VERSION "Emergency_System_CAN_Infotainment_v1.3"

NS_ :

BS_:

BU_: SIL_TEST_CTRL INFOTAINMENT_GW IVI_GW CLU_HMI_CTRL NAV_CONTEXT_MGR CLUSTER_BASE_CTRL Vector__XXX

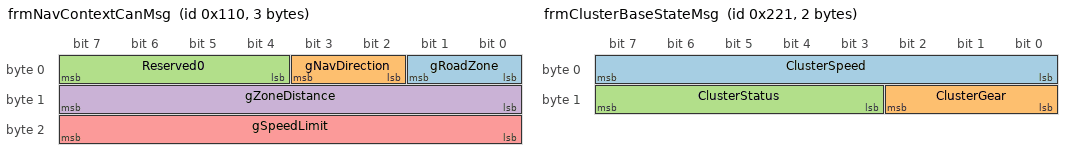
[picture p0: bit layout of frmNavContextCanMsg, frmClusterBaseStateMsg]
BO_ 272 frmNavContextCanMsg: 3 SIL_TEST_CTRL
 SG_ gRoadZone        : 0|2@1+ (1,0) [0|3] "" INFOTAINMENT_GW
 SG_ gNavDirection    : 2|2@1+ (1,0) [0|3] "" INFOTAINMENT_GW
 SG_ Reserved0        : 4|4@1+ (1,0) [0|0] "" Vector__XXX
 SG_ gZoneDistance    : 8|8@1+ (1,0) [0|255] "m" INFOTAINMENT_GW
 SG_ gSpeedLimit      : 16|8@1+ (1,0) [0|255] "km/h" INFOTAINMENT_GW

BO_ 544 frmClusterWarningMsg: 1 IVI_GW
 SG_ WarningTextCode  : 0|8@1+ (1,0) [0|255] "" CLU_HMI_CTRL

BO_ 545 frmClusterBaseStateMsg: 2 IVI_GW
 SG_ ClusterSpeed     : 0|8@1+ (1,0) [0|255] "km/h" CLUSTER_BASE_CTRL
 SG_ ClusterGear      : 8|3@1+ (1,0) [0|7] "" CLUSTER_BASE_CTRL
 SG_ ClusterStatus    : 11|5@1+ (1,0) [0|31] "" CLUSTER_BASE_CTRL

BO_ 546 frmNaviGuideStateMsg: 1 INFOTAINMENT_GW
 SG_ GuideLaneState   : 0|2@1+ (1,0) [0|3] "" NAV_CONTEXT_MGR
 SG_ GuideConfidence  : 2|6@1+ (1,0) [0|63] "" NAV_CONTEXT_MGR

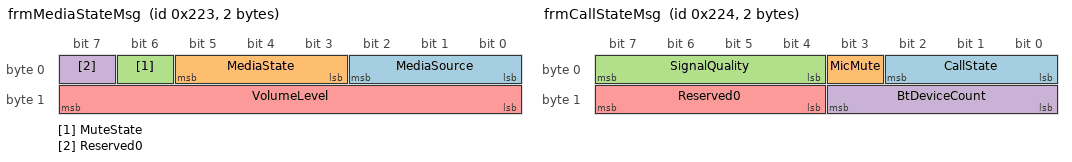
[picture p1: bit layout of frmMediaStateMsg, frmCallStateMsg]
BO_ 547 frmMediaStateMsg: 2 IVI_GW
 SG_ MediaSource      : 0|3@1+ (1,0) [0|7] "" CLU_HMI_CTRL
 SG_ MediaState       : 3|3@1+ (1,0) [0|7] "" CLU_HMI_CTRL
 SG_ MuteState        : 6|1@1+ (1,0) [0|1] "" CLU_HMI_CTRL
 SG_ Reserved0        : 7|1@1+ (1,0) [0|0] "" Vector__XXX
 SG_ VolumeLevel      : 8|8@1+ (1,0) [0|100] "%" CLU_HMI_CTRL

BO_ 548 frmCallStateMsg: 2 IVI_GW
 SG_ CallState        : 0|3@1+ (1,0) [0|7] "" CLU_HMI_CTRL
 SG_ MicMute          : 3|1@1+ (1,0) [0|1] "" CLU_HMI_CTRL
 SG_ SignalQuality    : 4|4@1+ (1,0) [0|15] "" CLU_HMI_CTRL
 SG_ BtDeviceCount    : 8|4@1+ (1,0) [0|15] "" CLU_HMI_CTRL
 SG_ Reserved0        : 12|4@1+ (1,0) [0|0] "" Vector__XXX

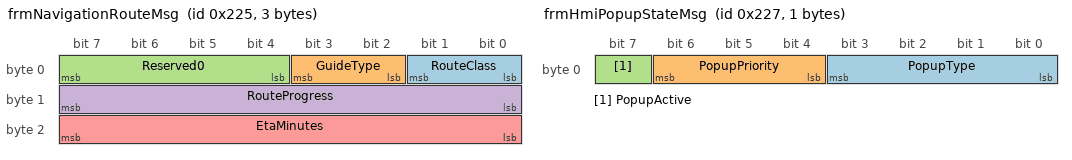
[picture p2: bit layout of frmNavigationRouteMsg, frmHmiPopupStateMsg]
BO_ 549 frmNavigationRouteMsg: 3 INFOTAINMENT_GW
 SG_ RouteClass       : 0|2@1+ (1,0) [0|3] "" NAV_CONTEXT_MGR
 SG_ GuideType        : 2|2@1+ (1,0) [0|3] "" NAV_CONTEXT_MGR
 SG_ Reserved0        : 4|4@1+ (1,0) [0|0] "" Vector__XXX
 SG_ RouteProgress    : 8|8@1+ (1,0) [0|100] "%" NAV_CONTEXT_MGR
 SG_ EtaMinutes       : 16|8@1+ (1,0) [0|255] "min" NAV_CONTEXT_MGR

BO_ 550 frmClusterThemeMsg: 1 IVI_GW
 SG_ ThemeMode        : 0|3@1+ (1,0) [0|7] "" CLUSTER_BASE_CTRL
 SG_ ClusterBrightness : 3|5@1+ (1,0) [0|31] "" CLUSTER_BASE_CTRL

BO_ 551 frmHmiPopupStateMsg: 1 IVI_GW
 SG_ PopupType        : 0|4@1+ (1,0) [0|15] "" CLU_HMI_CTRL
 SG_ PopupPriority    : 4|3@1+ (1,0) [0|7] "" CLU_HMI_CTRL
 SG_ PopupActive      : 7|1@1+ (1,0) [0|1] "" CLU_HMI_CTRL

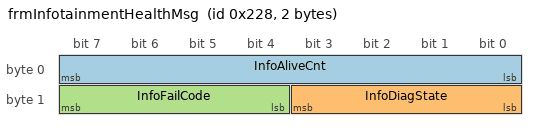
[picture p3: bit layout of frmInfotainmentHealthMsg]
BO_ 552 frmInfotainmentHealthMsg: 2 INFOTAINMENT_GW
 SG_ InfoAliveCnt     : 0|8@1+ (1,0) [0|255] "" SIL_TEST_CTRL
 SG_ InfoDiagState    : 8|4@1+ (1,0) [0|15] "" SIL_TEST_CTRL
 SG_ InfoFailCode     : 12|4@1+ (1,0) [0|15] "" SIL_TEST_CTRL

CM_ BU_ SIL_TEST_CTRL   "SIL test controller for CAN input injection.";
CM_ BU_ INFOTAINMENT_GW "Gateway: Infotainment CAN input normalization to core variables.";
CM_ BU_ IVI_GW          "Gateway: selected alert to Infotainment CAN (0x220).";
CM_ BU_ CLU_HMI_CTRL    "Cluster HMI ECU (consumer of 0x220).";
CM_ BU_ NAV_CONTEXT_MGR "Navigation context manager node (Flow_003 owner).";
CM_ BU_ CLUSTER_BASE_CTRL "Vehicle baseline cluster display node (Req_109).";
CM_ BU_ Vector__XXX     "Reserved node for unused or filler signals.";

CM_ BO_ 272 "Infotainment CAN input: road zone, direction, distance, and speed limit.";
CM_ BO_ 544 "Infotainment CAN output: cluster warning text code.";
CM_ BO_ 545 "Infotainment baseline: cluster base display payload (speed/gear/status).";
CM_ BO_ 546 "Infotainment baseline: lane guidance state and confidence.";
CM_ BO_ 547 "Infotainment baseline: media source/state/mute/volume.";
CM_ BO_ 548 "Infotainment baseline: call state, mute, and signal quality.";
CM_ BO_ 549 "Infotainment baseline: route class/progress/ETA.";
CM_ BO_ 550 "Infotainment baseline: cluster theme and brightness.";
CM_ BO_ 551 "Infotainment baseline: popup type/priority/active flag.";
CM_ BO_ 552 "Infotainment health/diagnostic state.";

CM_ "Domain split: infotainment CAN network from emergency_system.dbc baseline.";
CM_ "Post-mentoring alignment: infotainment domain node set expanded for baseline cluster context.";

BA_DEF_ BO_ "GenMsgCycleTime" INT 0 10000;
BA_DEF_DEF_ "GenMsgCycleTime" 0;

BA_ "GenMsgCycleTime" BO_ 272 100;
BA_ "GenMsgCycleTime" BO_ 544 50;
BA_ "GenMsgCycleTime" BO_ 545 50;
BA_ "GenMsgCycleTime" BO_ 546 100;
BA_ "GenMsgCycleTime" BO_ 547 100;
BA_ "GenMsgCycleTime" BO_ 548 100;
BA_ "GenMsgCycleTime" BO_ 549 100;
BA_ "GenMsgCycleTime" BO_ 550 50;
BA_ "GenMsgCycleTime" BO_ 551 50;
BA_ "GenMsgCycleTime" BO_ 552 100;

  0 "Normal"
  1 "SchoolZone"
  2 "Highway"
  3 "Guide" ;

  0 "None"
  1 "Left"
  2 "Right"
  3 "Other" ;

  0 "None"
  1 "Left"
  2 "Right"
  3 "Merge" ;

  0 "None"
  1 "Radio"
  2 "Bluetooth"
  3 "USB"
  4 "Streaming"
  5 "NaviVoice"
  6 "Reserved6"
  7 "Reserved7" ;

  0 "Stopped"
  1 "Playing"
  2 "Paused"
  3 "Buffering"
  4 "Error"
  5 "Reserved5"
  6 "Reserved6"
  7 "Reserved7" ;

  0 "Unmuted"
  1 "Muted" ;

  0 "Idle"
  1 "Ringing"
  2 "Connected"
  3 "OnHold"
  4 "Ended"
  5 "Reserved5"
  6 "Reserved6"
  7 "Reserved7" ;

  0 "Off"
  1 "On" ;

  0 "Local"
  1 "Primary"
  2 "Highway"
  3 "Mixed" ;

  0 "None"
  1 "Turn"
  2 "LaneChange"
  3 "Exit" ;

  0 "Default"
  1 "Sport"
  2 "Comfort"
  3 "Eco"
  4 "Night"
  5 "Alert"
  6 "Reserved6"
  7 "Reserved7" ;

  0 "Inactive"
  1 "Active" ;
